# M369 register map
File version: 0.1
CPU: 
Registers are 32-bit, read-write, reset 0x0 unless marked. A register's access mark holds for its fields unless they carry their own. Offsets are from the block's base; [hi:lo] are bit positions; {n}, {i} and the like mark numbered series.

## PH — General Purpose Input_Output Port (PH)
Base 0x400C0700
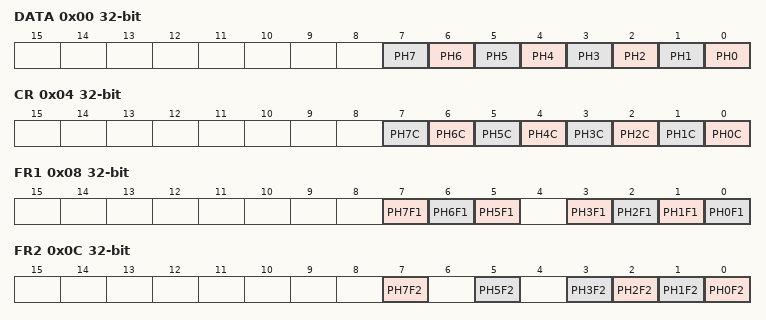
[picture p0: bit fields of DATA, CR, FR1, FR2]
0x00 DATA — PH Data Register
  [n] PH{n} (n=0..7)
0x04 CR — PH Control Register
  [n] PH{n}C (n=0..7)
0x08 FR1 — PH Function Register 1
  [7] PH7F1, [6] PH6F1, [5] PH5F1, [n] PH{n}F1 (n=0..3)
0x0C FR2 — PH Function Register 2
  [7] PH7F2, [5] PH5F2, [n] PH{n}F2 (n=0..3)
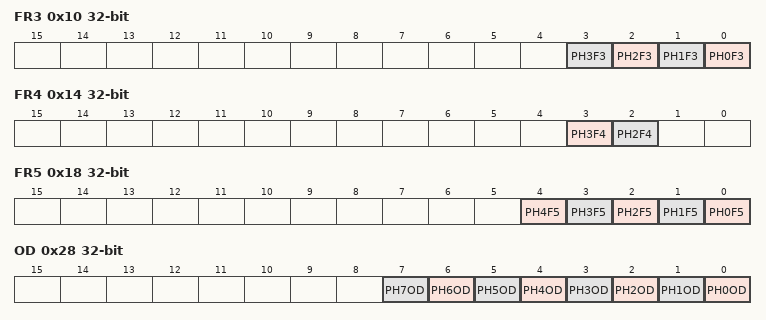
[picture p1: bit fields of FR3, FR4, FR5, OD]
0x10 FR3 — PH Function Register 3
  [n] PH{n}F3 (n=0..3)
0x14 FR4 — PH Function Register 4
  [3] PH3F4, [2] PH2F4
0x18 FR5 — PH Function Register 5
  [n] PH{n}F5 (n=0..4)
0x28 OD — PH Open Drain Control Register
  [n] PH{n}OD (n=0..7)
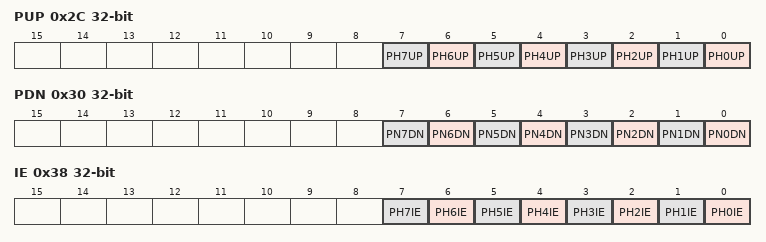
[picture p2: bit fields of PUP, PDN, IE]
0x2C PUP — PH Pull-Up Control Register
  [n] PH{n}UP (n=0..7)
0x30 PDN — PH Pull-Down Control Register
  [n] PN{n}DN (n=0..7)
0x38 IE — PH Input Enable Control Register
  [n] PH{n}IE (n=0..7)

## PI — General Purpose Input_Output Port (PI)
Base 0x400C0800
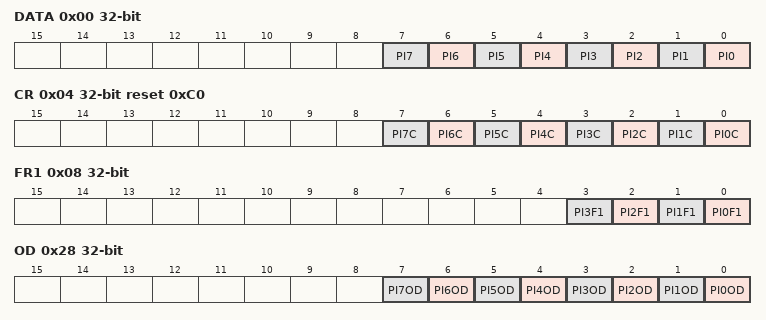
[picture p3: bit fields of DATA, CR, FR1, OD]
0x00 DATA — PI Data Register
  [n] PI{n} (n=0..7)
0x04 CR reset 0xC0 — PI Control Register
  [n] PI{n}C (n=0..7)
0x08 FR1 — PI Function Register 1
  [n] PI{n}F1 (n=0..3)
0x0C FR2 — PI Function Register 2
  [3] PI3F2
0x28 OD — PI Open Drain Control Register
  [n] PI{n}OD (n=0..7)
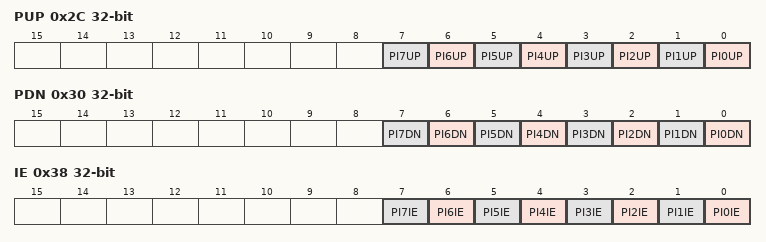
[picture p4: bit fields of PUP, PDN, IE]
0x2C PUP — PI Pull-Up Control Register
  [n] PI{n}UP (n=0..7)
0x30 PDN — PI Pull-Down Control Register
  [n] PI{n}DN (n=0..7)
0x38 IE — PI Input Enable Control Register
  [n] PI{n}IE (n=0..7)

## PJ — General Purpose Input_Output Port (PJ)
Base 0x400C0900
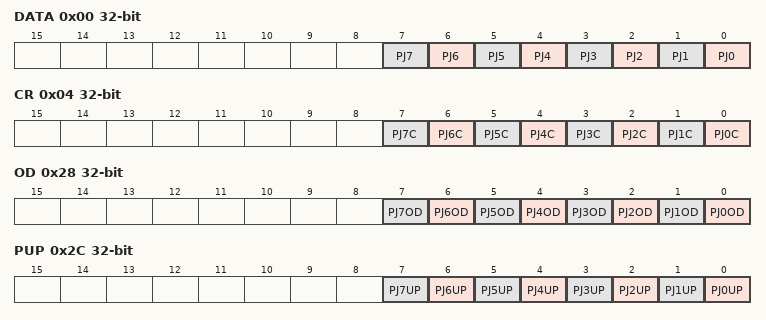
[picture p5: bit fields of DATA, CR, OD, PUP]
0x00 DATA — PJ Data Register
  [n] PJ{n} (n=0..7)
0x04 CR — PJ Control Register
  [n] PJ{n}C (n=0..7)
0x28 OD — PJ Open Drain Control Register
  [n] PJ{n}OD (n=0..7)
0x2C PUP — PJ Pull-Up Control Register
  [n] PJ{n}UP (n=0..7)
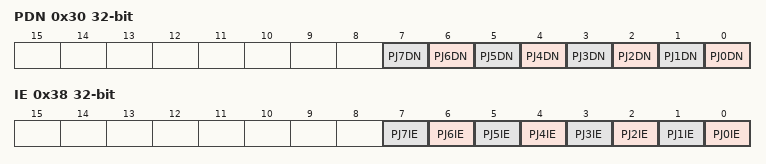
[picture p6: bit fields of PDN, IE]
0x30 PDN — PJ Pull-Down Control Register
  [n] PJ{n}DN (n=0..7)
0x38 IE — PJ Input Enable Control Register
  [n] PJ{n}IE (n=0..7)

## PK — General Purpose Input_Output Port (PK)
Base 0x400C0A00
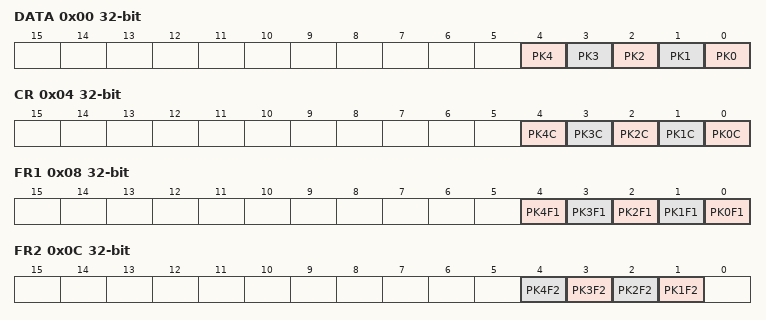
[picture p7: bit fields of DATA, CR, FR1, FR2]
0x00 DATA — PK Data Register
  [n] PK{n} (n=0..4)
0x04 CR — PK Control Register
  [n] PK{n}C (n=0..4)
0x08 FR1 — PK Function Register 1
  [n] PK{n}F1 (n=0..4)
0x0C FR2 — PK Function Register 2
  [n] PK{n}F2 (n=1..4)
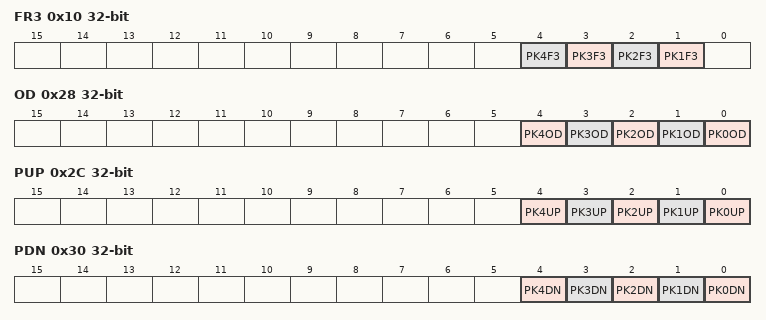
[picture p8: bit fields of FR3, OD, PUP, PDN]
0x10 FR3 — PK Function Register 3
  [n] PK{n}F3 (n=1..4)
0x14 FR4 — PK Function Register 4
  [1] PK1F4
0x28 OD — PK Open Drain Control Register
  [n] PK{n}OD (n=0..4)
0x2C PUP — PK Pull-Up Control Register
  [n] PK{n}UP (n=0..4)
0x30 PDN — PK Pull-Down Control Register
  [n] PK{n}DN (n=0..4)
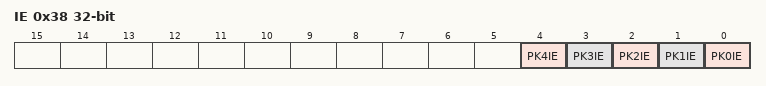
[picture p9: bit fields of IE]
0x38 IE — PK Input Enable Control Register
  [n] PK{n}IE (n=0..4)

## PL — General Purpose Input_Output Port (PL)
Base 0x400C0B00
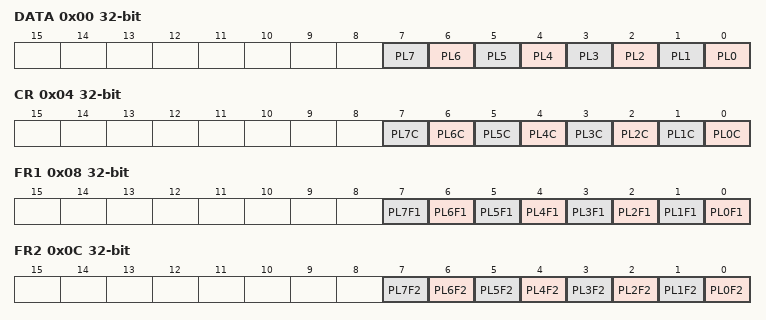
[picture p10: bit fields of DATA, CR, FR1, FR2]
0x00 DATA — PL Data Register
  [n] PL{n} (n=0..7)
0x04 CR — PL Control Register
  [n] PL{n}C (n=0..7)
0x08 FR1 — PL Function Register 1
  [n] PL{n}F1 (n=0..7)
0x0C FR2 — PL Function Register 2
  [n] PL{n}F2 (n=0..7)
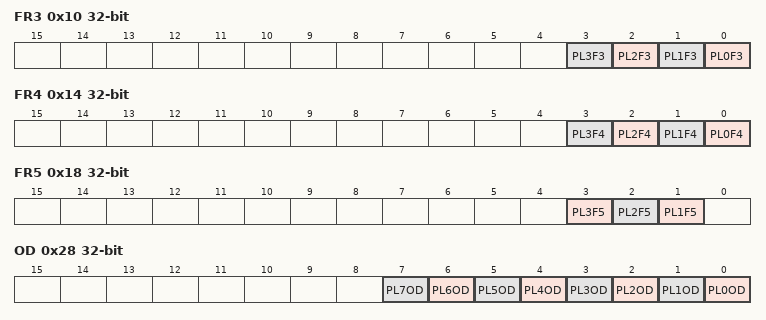
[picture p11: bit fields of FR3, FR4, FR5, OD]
0x10 FR3 — PL Function Register 3
  [n] PL{n}F3 (n=0..3)
0x14 FR4 — PL Function Register 4
  [n] PL{n}F4 (n=0..3)
0x18 FR5 — PL Function Register 5
  [3] PL3F5, [2] PL2F5, [1] PL1F5
0x1C FR6 — PL Function Register 6
  [3] PL3F6
0x28 OD — PL Open Drain Control Register
  [n] PL{n}OD (n=0..7)
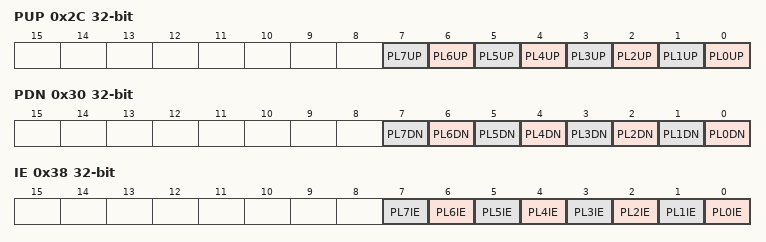
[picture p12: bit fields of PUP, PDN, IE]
0x2C PUP — PL Pull-Up Control Register
  [n] PL{n}UP (n=0..7)
0x30 PDN — PL Pull-Down Control Register
  [n] PL{n}DN (n=0..7)
0x38 IE — PL Input Enable Control Register
  [n] PL{n}IE (n=0..7)

## PM — General Purpose Input_Output Port (PM)
Base 0x400C0C00
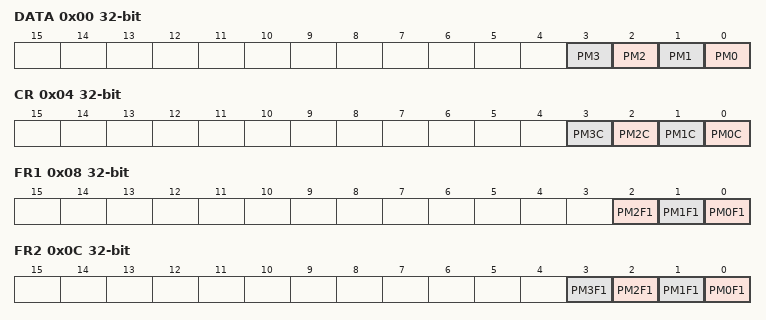
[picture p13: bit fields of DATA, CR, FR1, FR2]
0x00 DATA — PM Data Register
  [n] PM{n} (n=0..3)
0x04 CR — PM Control Register
  [n] PM{n}C (n=0..3)
0x08 FR1 — PM Function Register 1
  [2] PM2F1, [1] PM1F1, [0] PM0F1
0x0C FR2 — PM Function Register 2
  [n] PM{n}F1 (n=0..3)
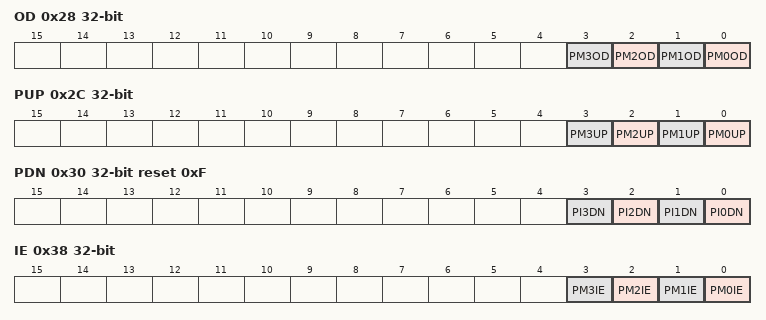
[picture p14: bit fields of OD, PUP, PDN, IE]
0x28 OD — PM Open Drain Control Register
  [n] PM{n}OD (n=0..3)
0x2C PUP — PM Pull-Up Control Register
  [n] PM{n}UP (n=0..3)
0x30 PDN reset 0xF — PM Pull-Down Control Register
  [n] PI{n}DN (n=0..3)
0x38 IE — PM Input Enable Control Register
  [n] PM{n}IE (n=0..3)
